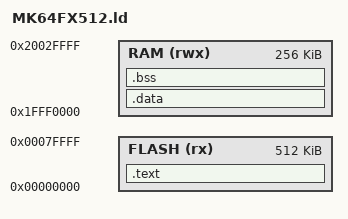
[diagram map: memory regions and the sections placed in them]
MEMORY
{
    FLASH (rx)  : ORIGIN = 0x00000000, LENGTH = 512K
    RAM   (rwx) : ORIGIN = 0x1FFF0000, LENGTH = 256K
}

ENTRY(Reset_Handler)

SECTIONS
{
    .text :
    {
        KEEP(*(.vectors))
        *(.text*)
        *(.rodata*)
        . = ALIGN(4);
        _etext = .;
    } > FLASH

    .data : AT(_etext)
    {
        _sdata = .;
        *(.data*)
        . = ALIGN(4);
        _edata = .;
    } > RAM

    .bss :
    {
        _sbss = .;
        *(.bss*)
        *(COMMON)
        . = ALIGN(4);
        _ebss = .;
    } > RAM
}
